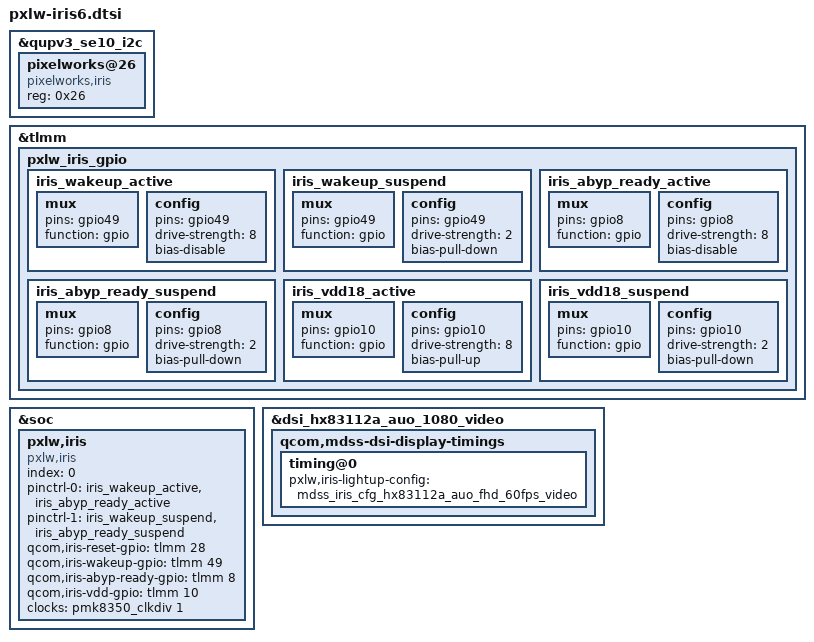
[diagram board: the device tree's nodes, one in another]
/* Copyright (c) 2020, Pixelworks
 *
 * This program is free software; you can redistribute it and/or modify
 * it under the terms of the GNU General Public License version 2 and
 * only version 2 as published by the Free Software Foundation.
 *
 * This program is distributed in the hope that it will be useful,
 * but WITHOUT ANY WARRANTY; without even the implied warranty of
 * MERCHANTABILITY or FITNESS FOR A PARTICULAR PURPOSE.  See the
 * GNU General Public License for more details.
 */

#include "pxlw-iris6-cfg-dsi-panel-hx83112a-auo-1080p-video.dtsi"

&qupv3_se10_i2c {
	//qcom,clk-freq-out = <1000000>;
        status = "ok";
        pixelworks@26 {  //i2c: 22, i3c: 26
                status = "ok";
                compatible = "pixelworks,iris";
                reg = <0x26>;
        };
};

&tlmm {
	pxlw_iris_gpio: pxlw_iris_gpio {
		iris_wakeup_active: iris_wakeup_active {
			mux {
				pins = "gpio49";
				function = "gpio";
			};

			config {
				pins = "gpio49";
				drive-strength = <8>;
				bias-disable;
			};
		};

		iris_wakeup_suspend: iris_wakeup_suspend {
			mux {
				pins = "gpio49";
				function = "gpio";
			};

			config {
				pins = "gpio49";
				drive-strength = <2>;
				bias-pull-down;
			};
		};

		iris_abyp_ready_active: iris_abyp_ready_active {
			mux {
				pins = "gpio8";
				function = "gpio";
			};

			config {
				pins = "gpio8";
				drive-strength = <8>;
				bias-disable;
			};
		};

		iris_abyp_ready_suspend: iris_abyp_ready_suspend {
			mux {
				pins = "gpio8";
				function = "gpio";
			};

			config {
				pins = "gpio8";
				drive-strength = <2>;
				bias-pull-down;
			};
		};
		iris_vdd18_active: iris_vdd18_active {
			mux {
				pins = "gpio10";
				function = "gpio";
			};

			config {
				pins = "gpio10";
				drive-strength = <8>;
				bias-pull-up;
			};
		};

		iris_vdd18_suspend: iris_vdd18_suspend {
			mux {
				pins = "gpio10";
				function = "gpio";
			};

			config {
				pins = "gpio10";
				drive-strength = <2>;
				bias-pull-down;
			};
		};
	};
};

&soc {
	pxlw,iris {
		compatible = "pxlw,iris";
		index = <0>;

		pinctrl-names = "iris_active", "iris_suspend";
		pinctrl-0 = <&iris_wakeup_active &iris_abyp_ready_active>;
		pinctrl-1 = <&iris_wakeup_suspend &iris_abyp_ready_suspend>;

		qcom,iris-reset-gpio = <&tlmm 28 0>;
		qcom,iris-wakeup-gpio = <&tlmm 49 0>;
		qcom,iris-abyp-ready-gpio = <&tlmm 8 0>;
		qcom,iris-vdd-gpio = <&tlmm 10 0>;

		clocks = <&pmk8350_clkdiv 1>;
		clock-names = "iris_clk";
	};
};

&dsi_hx83112a_auo_1080_video {
	qcom,mdss-dsi-display-timings {
		timing@0{
			pxlw,iris-lightup-config = <&mdss_iris_cfg_hx83112a_auo_fhd_60fps_video>;
		};
	};
};
